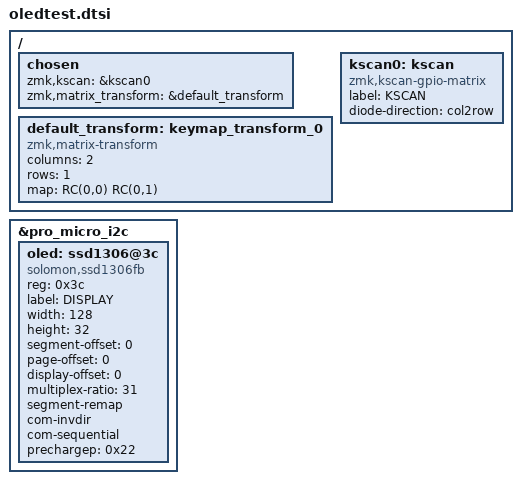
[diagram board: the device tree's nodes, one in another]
/*
 * Copyright (c) 2020 Derek Schmell
 *
 * SPDX-License-Identifier: MIT
 */

#include <dt-bindings/zmk/matrix-transform.h>

/ {
	chosen {
		zmk,kscan = &kscan0;
		zmk,matrix_transform = &default_transform;
	};

	default_transform: keymap_transform_0 {
		compatible = "zmk,matrix-transform";
		columns = <2>;
		rows = <1>;
		map = <
			RC(0,0) RC(0,1)
		>;
	};

	kscan0: kscan {
		compatible = "zmk,kscan-gpio-matrix";
		label = "KSCAN";

		diode-direction = "col2row";
	};
};

&pro_micro_i2c {
	status = "okay";

	oled: ssd1306@3c {
		compatible = "solomon,ssd1306fb";
		reg = <0x3c>;
		label = "DISPLAY";
		width = <128>;
		height = <32>;
		segment-offset = <0>;
		page-offset = <0>;
		display-offset = <0>;
		multiplex-ratio = <31>;
		segment-remap;
		com-invdir;
		com-sequential;
		prechargep = <0x22>;
	};
};
